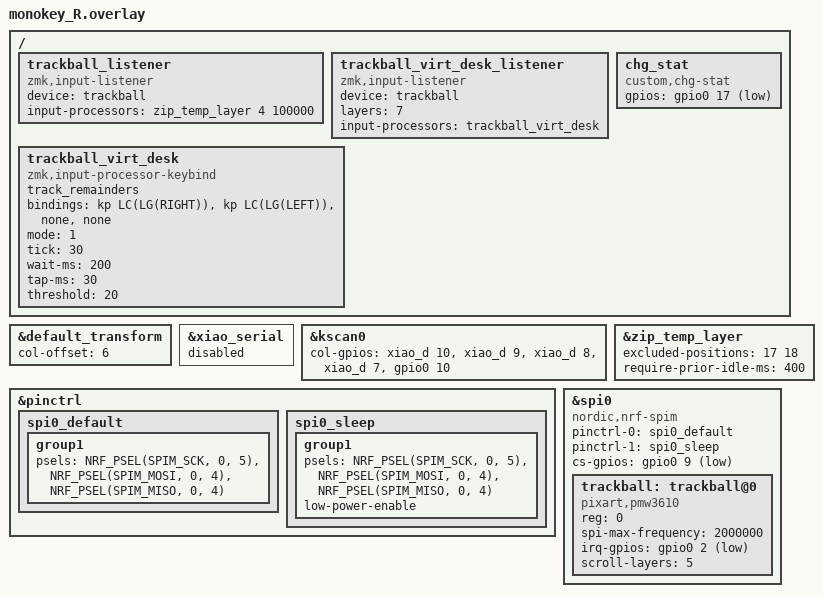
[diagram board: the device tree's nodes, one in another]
#include "monokey.dtsi"
#include <input/processors.dtsi>
#include <input/processors/zmk-input-processor-keybind.dtsi>

&default_transform {
    col-offset = <6>;
};

&xiao_serial { status = "disabled"; };

&kscan0 {
        col-gpios
            = <&xiao_d 10 GPIO_ACTIVE_HIGH>
            , <&xiao_d 9 GPIO_ACTIVE_HIGH> 
            , <&xiao_d 8 GPIO_ACTIVE_HIGH> 
            , <&xiao_d 7 GPIO_ACTIVE_HIGH> 
            , <&gpio0 10 GPIO_ACTIVE_HIGH>
            ;
};



// 非マウスキーでAML解除
&zip_temp_layer {
    excluded-positions = <
        17 // K
        18 // L
    >;
    require-prior-idle-ms = <400>;
    // トラボ誤爆防止
};


/ {
    trackball_listener {
        compatible = "zmk,input-listener";
        device = <&trackball>;
        input-processors = <&zip_temp_layer 4 100000>; // AML

    };

    // 仮想デスクトップ移動: K+L 同時押し（レイヤー7）中のみ動作
    trackball_virt_desk_listener {
        compatible = "zmk,input-listener";
        device = <&trackball>;
        layers = <7>;
        input-processors = <&trackball_virt_desk>;
    };

    trackball_virt_desk: trackball_virt_desk {
        compatible = "zmk,input-processor-keybind";
        #input-processor-cells = <0>;
        track_remainders;
        // 順序: RIGHT(X+), LEFT(X-), DOWN(Y+), UP(Y-)
        bindings =
            <&kp LC(LG(RIGHT))>,  // 右に動かす → 右デスクトップへ
            <&kp LC(LG(LEFT))>,   // 左に動かす → 左デスクトップへ
            <&none>,              // Y軸は使わない
            <&none>;
        mode = <1>;         // 4方向DPad（左右のみ使用）
        tick = <30>;        // この単位ごとに1回発火（低いほど高感度）
        wait-ms = <200>;    // 切り替えアニメーション中に次が発火しないよう余裕を持つ
        tap-ms = <30>;
        threshold = <20>;   // 誤爆防止デッドゾーン
    };

    chg_stat: chg_stat {
        compatible = "custom,chg-stat";
        /* Xiao BLE の充電検知ピン P0.17 (Low = 充電中, High = 完了/未接続) */
        gpios = <&gpio0 17 GPIO_ACTIVE_LOW>;
        status = "okay";
    };
};

&pinctrl {
    spi0_default: spi0_default {
        group1 {
            psels = <NRF_PSEL(SPIM_SCK, 0, 5)>,
                <NRF_PSEL(SPIM_MOSI, 0, 4)>,
                <NRF_PSEL(SPIM_MISO, 0, 4)>;
        };
    };

    spi0_sleep: spi0_sleep {
        group1 {
            psels = <NRF_PSEL(SPIM_SCK, 0, 5)>,
                <NRF_PSEL(SPIM_MOSI, 0, 4)>,
                <NRF_PSEL(SPIM_MISO, 0, 4)>;
            low-power-enable;
        };
    };
};

&spi0 {
    status = "okay";
    compatible = "nordic,nrf-spim";
    pinctrl-0 = <&spi0_default>;
    pinctrl-1 = <&spi0_sleep>;
    pinctrl-names = "default", "sleep";
    cs-gpios = <&gpio0 9 GPIO_ACTIVE_LOW>;

    trackball: trackball@0 {
        status = "okay";
        compatible = "pixart,pmw3610";
        reg = <0>;
        spi-max-frequency = <2000000>;
        irq-gpios = <&gpio0 2 (GPIO_ACTIVE_LOW | GPIO_PULL_UP)>;
        scroll-layers = <5>;
    };
};
